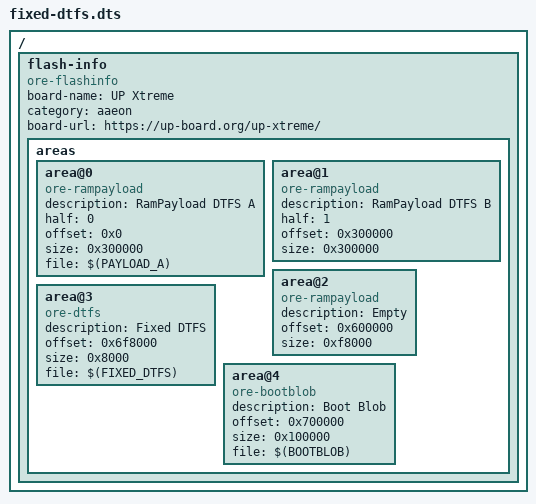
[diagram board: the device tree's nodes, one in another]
/dts-v1/;

/ {
    #address-cells = <1>;
    #size-cells = <1>;

    flash-info {
        compatible = "ore-flashinfo";
        board-name = "UP Xtreme";
        category = "aaeon";
        board-url = "https://up-board.org/up-xtreme/";
        areas {
            area@0 {
                description = "RamPayload DTFS A";
                compatible = "ore-rampayload";
                half = <0>;
                offset = <0x0>;
                size = <0x300000>;
                file = "$(PAYLOAD_A)";
            };
            area@1 {
                description = "RamPayload DTFS B";
                compatible = "ore-rampayload";
                half = <1>;
                offset = <0x300000>;
                size = <0x300000>;
            };
            area@2 {
                description = "Empty";
                compatible = "ore-rampayload";
                offset = <0x600000>;
                size = <0xf8000>;
            };
            area@3 {
                description = "Fixed DTFS";
                compatible = "ore-dtfs";
                offset = <0x6f8000>;
                size = <0x8000>;
                file = "$(FIXED_DTFS)";
            };
            area@4 {
                description = "Boot Blob";
                compatible = "ore-bootblob";
                offset = <0x700000>;
                size = <0x100000>;
                file = "$(BOOTBLOB)";
            };
        };
    };
};
